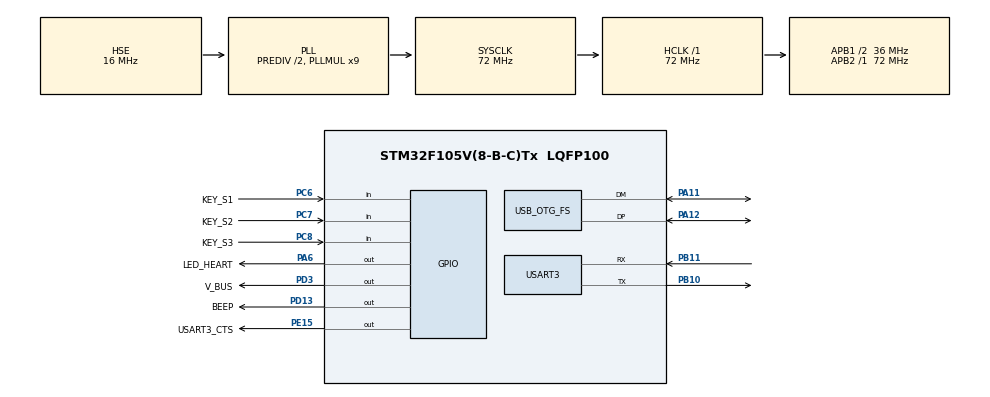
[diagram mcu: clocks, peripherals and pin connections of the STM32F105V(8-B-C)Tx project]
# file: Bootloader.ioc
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Dma.Request0=USART3_RX
Dma.Request1=USART3_TX
Dma.USART3_RX.0.Direction=DMA_PERIPH_TO_MEMORY
Dma.USART3_RX.0.Instance=DMA1_Channel3
Dma.USART3_RX.0.MemDataAlignment=DMA_MDATAALIGN_BYTE
Dma.USART3_RX.0.MemInc=DMA_MINC_ENABLE
Dma.USART3_RX.0.Mode=DMA_CIRCULAR
Dma.USART3_RX.0.PeriphDataAlignment=DMA_PDATAALIGN_BYTE
Dma.USART3_RX.0.PeriphInc=DMA_PINC_DISABLE
Dma.USART3_RX.0.Priority=DMA_PRIORITY_LOW
Dma.USART3_TX.1.Direction=DMA_MEMORY_TO_PERIPH
Dma.USART3_TX.1.Instance=DMA1_Channel2
Dma.USART3_TX.1.MemDataAlignment=DMA_MDATAALIGN_BYTE
Dma.USART3_TX.1.MemInc=DMA_MINC_ENABLE
Dma.USART3_TX.1.Mode=DMA_CIRCULAR
Dma.USART3_TX.1.PeriphDataAlignment=DMA_PDATAALIGN_BYTE
Dma.USART3_TX.1.PeriphInc=DMA_PINC_DISABLE
Dma.USART3_TX.1.Priority=DMA_PRIORITY_LOW
FATFS._FS_LOCK=1
FATFS._FS_NOFSINFO=0
FATFS._MAX_LFN=255
FATFS._MAX_SS=4096
FATFS._USE_LFN=1
Mcu.Family=STM32F1
Mcu.Name=STM32F105V(8-B-C)Tx
Mcu.Package=LQFP100
NVIC.DMA1_Channel2_IRQn=true\:0\:0\:false\:false\:true\:false\:true\:true
NVIC.DMA1_Channel3_IRQn=true\:0\:0\:false\:false\:true\:false\:true\:true
NVIC.OTG_FS_IRQn=true\:0\:0\:false\:false\:true\:false\:true\:true
NVIC.PriorityGroup=NVIC_PRIORITYGROUP_4
OSC_IN.Mode=HSE-External-Oscillator
OSC_IN.Signal=RCC_OSC_IN
OSC_OUT.Mode=HSE-External-Oscillator
OSC_OUT.Signal=RCC_OSC_OUT
PA11.Mode=Host_Only
PA11.Signal=USB_OTG_FS_DM
PA12.Mode=Host_Only
PA12.Signal=USB_OTG_FS_DP
PA13.Mode=Serial_Wire
PA13.Signal=SYS_JTMS-SWDIO
PA14.Mode=Serial_Wire
PA14.Signal=SYS_JTCK-SWCLK
PA6.GPIO_Label=LED_HEART
PA6.Signal=GPIO_Output
PB10.Mode=Asynchronous
PB10.Signal=USART3_TX
PB11.Mode=Asynchronous
PB11.Signal=USART3_RX
PC6.GPIO_Label=KEY_S1
PC6.Signal=GPIO_Input
PC7.GPIO_Label=KEY_S2
PC7.Signal=GPIO_Input
PC8.GPIO_Label=KEY_S3
PC8.Signal=GPIO_Input
PD13.GPIO_Label=BEEP
PD13.Signal=GPIO_Output
PD3.GPIO_Label=V_BUS
PD3.Signal=GPIO_Output
PE15.GPIO_Label=USART3_CTS
PE15.Signal=GPIO_Output
ProjectManager.HeapSize=0x200
ProjectManager.StackSize=0x400
ProjectManager.TargetToolchain=STM32CubeIDE
RCC.AHBFreq_Value=72000000
RCC.APB1CLKDivider=RCC_HCLK_DIV2
RCC.APB1Freq_Value=36000000
RCC.APB1TimFreq_Value=72000000
RCC.APB2Freq_Value=72000000
RCC.APB2TimFreq_Value=72000000
RCC.HCLKFreq_Value=72000000
RCC.HSEDivPLL=RCC_HSE_PREDIV_DIV2
RCC.HSE_VALUE=16000000
RCC.PLLMUL=RCC_PLL_MUL9
RCC.PLLSourceVirtual=RCC_PLLSOURCE_HSE
RCC.SYSCLKFreq_VALUE=72000000
RCC.SYSCLKSource=RCC_SYSCLKSOURCE_PLLCLK
RCC.USBFreq_Value=48000000
USART3.VirtualMode=VM_ASYNC
USB_HOST.BSP.number=1
USB_HOST.USBH_HandleTypeDef=hUsbHostFS
USB_HOST.VirtualModeFS=Msc
USB_HOST0.BSP.STBoard=false
USB_HOST0.BSP.api=Unknown
USB_HOST0.BSP.instance=PD3
USB_HOST0.BSP.ip=GPIO
USB_HOST0.BSP.mode=Output
USB_HOST0.BSP.name=Drive_VBUS_FS
USB_HOST0.BSP.solution=PD3
USB_OTG_FS.VirtualMode=Host_Only
VP_FATFS_VS_USB.Mode=USB
VP_USB_HOST_VS_USB_HOST_MSC_FS.Mode=MSC_FS
board=custom

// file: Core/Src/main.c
/* USER CODE BEGIN Header */
/**
  ******************************************************************************
  * @file           : main.c
  * @brief          : Main program body
  ******************************************************************************
  * @attention
  *
  * Copyright (c) 2023 STMicroelectronics.
  * All rights reserved.
  *
  * This software is licensed under terms that can be found in the LICENSE file
  * in the root directory of this software component.
  * If no LICENSE file comes with this software, it is provided AS-IS.
  *
  ******************************************************************************
  */
/* USER CODE END Header */
#include "main.h"
#include "fatfs.h"
#include "usb_host.h"

/* USER CODE BEGIN Includes */
#include "serial.h"
#include "Inc/DB_Protocol.h"
#include "_ver.h"

/* USER CODE END Includes */

UART_HandleTypeDef huart3;
DMA_HandleTypeDef hdma_usart3_rx;
DMA_HandleTypeDef hdma_usart3_tx;

void SystemClock_Config(void);
static void MX_GPIO_Init(void);
static void MX_DMA_Init(void);
static void MX_USART3_UART_Init(void);
void MX_USB_HOST_Process(void);

int main(void)
{

  /* MCU Configuration--------------------------------------------------------*/

  /* Reset of all peripherals, Initializes the Flash interface and the Systick. */
  HAL_Init();

  /* Configure the system clock */
  SystemClock_Config();

  /* Initialize all configured peripherals */
  MX_GPIO_Init();
  MX_DMA_Init();
  MX_FATFS_Init();
  MX_USB_HOST_Init();
  MX_USART3_UART_Init();
  /* USER CODE BEGIN 2 */
//jumpToApp(0x800C800);
	BootloaderInit();
 /* USER CODE END 2 */

  /* Infinite loop */
  while (1)
  {
    MX_USB_HOST_Process();

  }
}

void SystemClock_Config(void)
{
  RCC_OscInitTypeDef RCC_OscInitStruct = {0};
  RCC_ClkInitTypeDef RCC_ClkInitStruct = {0};
  RCC_PeriphCLKInitTypeDef PeriphClkInit = {0};

  /** Initializes the RCC Oscillators according to the specified parameters
  * in the RCC_OscInitTypeDef structure.
  */
  RCC_OscInitStruct.OscillatorType = RCC_OSCILLATORTYPE_HSE;
  RCC_OscInitStruct.HSEState = RCC_HSE_ON;
  RCC_OscInitStruct.HSEPredivValue = RCC_HSE_PREDIV_DIV2;
  RCC_OscInitStruct.HSIState = RCC_HSI_ON;
  RCC_OscInitStruct.Prediv1Source = RCC_PREDIV1_SOURCE_HSE;
  RCC_OscInitStruct.PLL.PLLState = RCC_PLL_ON;
  RCC_OscInitStruct.PLL.PLLSource = RCC_PLLSOURCE_HSE;
  RCC_OscInitStruct.PLL.PLLMUL = RCC_PLL_MUL9;
  RCC_OscInitStruct.PLL2.PLL2State = RCC_PLL_NONE;
  if (HAL_RCC_OscConfig(&RCC_OscInitStruct) != HAL_OK)
  {
    Error_Handler();
  }

  /** Initializes the CPU, AHB and APB buses clocks
  */
  RCC_ClkInitStruct.ClockType = RCC_CLOCKTYPE_HCLK|RCC_CLOCKTYPE_SYSCLK
                              |RCC_CLOCKTYPE_PCLK1|RCC_CLOCKTYPE_PCLK2;
  RCC_ClkInitStruct.SYSCLKSource = RCC_SYSCLKSOURCE_PLLCLK;
  RCC_ClkInitStruct.AHBCLKDivider = RCC_SYSCLK_DIV1;
  RCC_ClkInitStruct.APB1CLKDivider = RCC_HCLK_DIV2;
  RCC_ClkInitStruct.APB2CLKDivider = RCC_HCLK_DIV1;

  if (HAL_RCC_ClockConfig(&RCC_ClkInitStruct, FLASH_LATENCY_2) != HAL_OK)
  {
    Error_Handler();
  }
  PeriphClkInit.PeriphClockSelection = RCC_PERIPHCLK_USB;
  PeriphClkInit.UsbClockSelection = RCC_USBCLKSOURCE_PLL_DIV3;
  if (HAL_RCCEx_PeriphCLKConfig(&PeriphClkInit) != HAL_OK)
  {
    Error_Handler();
  }

  /** Configure the Systick interrupt time
  */
  __HAL_RCC_PLLI2S_ENABLE();
}

static void MX_USART3_UART_Init(void)
{

  huart3.Instance = USART3;
  huart3.Init.BaudRate = 115200;
  huart3.Init.WordLength = UART_WORDLENGTH_8B;
  huart3.Init.StopBits = UART_STOPBITS_1;
  huart3.Init.Parity = UART_PARITY_NONE;
  huart3.Init.Mode = UART_MODE_TX_RX;
  huart3.Init.HwFlowCtl = UART_HWCONTROL_NONE;
  huart3.Init.OverSampling = UART_OVERSAMPLING_16;
  if (HAL_UART_Init(&huart3) != HAL_OK)
  {
    Error_Handler();
  }

}

static void MX_DMA_Init(void)
{

  /* DMA controller clock enable */
  __HAL_RCC_DMA1_CLK_ENABLE();

  /* DMA interrupt init */
  /* DMA1_Channel2_IRQn interrupt configuration */
  HAL_NVIC_SetPriority(DMA1_Channel2_IRQn, 0, 0);
  HAL_NVIC_EnableIRQ(DMA1_Channel2_IRQn);
  /* DMA1_Channel3_IRQn interrupt configuration */
  HAL_NVIC_SetPriority(DMA1_Channel3_IRQn, 0, 0);
  HAL_NVIC_EnableIRQ(DMA1_Channel3_IRQn);

}

static void MX_GPIO_Init(void)
{
  GPIO_InitTypeDef GPIO_InitStruct = {0};

  /* GPIO Ports Clock Enable */
  __HAL_RCC_GPIOA_CLK_ENABLE();
  __HAL_RCC_GPIOE_CLK_ENABLE();
  __HAL_RCC_GPIOB_CLK_ENABLE();
  __HAL_RCC_GPIOD_CLK_ENABLE();
  __HAL_RCC_GPIOC_CLK_ENABLE();

  /*Configure GPIO pin Output Level */
  HAL_GPIO_WritePin(LED_HEART_GPIO_Port, LED_HEART_Pin, GPIO_PIN_RESET);

  /*Configure GPIO pin Output Level */
  HAL_GPIO_WritePin(USART3_CTS_GPIO_Port, USART3_CTS_Pin, GPIO_PIN_RESET);

  /*Configure GPIO pin Output Level */
  HAL_GPIO_WritePin(GPIOD, BEEP_Pin|V_BUS_Pin, GPIO_PIN_RESET);

  /*Configure GPIO pin : LED_HEART_Pin */
  GPIO_InitStruct.Pin = LED_HEART_Pin;
  GPIO_InitStruct.Mode = GPIO_MODE_OUTPUT_PP;
  GPIO_InitStruct.Pull = GPIO_NOPULL;
  GPIO_InitStruct.Speed = GPIO_SPEED_FREQ_LOW;
  HAL_GPIO_Init(LED_HEART_GPIO_Port, &GPIO_InitStruct);

  /*Configure GPIO pin : USART3_CTS_Pin */
  GPIO_InitStruct.Pin = USART3_CTS_Pin;
  GPIO_InitStruct.Mode = GPIO_MODE_OUTPUT_PP;
  GPIO_InitStruct.Pull = GPIO_NOPULL;
  GPIO_InitStruct.Speed = GPIO_SPEED_FREQ_LOW;
  HAL_GPIO_Init(USART3_CTS_GPIO_Port, &GPIO_InitStruct);

  /*Configure GPIO pins : BEEP_Pin V_BUS_Pin */
  GPIO_InitStruct.Pin = BEEP_Pin|V_BUS_Pin;
  GPIO_InitStruct.Mode = GPIO_MODE_OUTPUT_PP;
  GPIO_InitStruct.Pull = GPIO_NOPULL;
  GPIO_InitStruct.Speed = GPIO_SPEED_FREQ_LOW;
  HAL_GPIO_Init(GPIOD, &GPIO_InitStruct);

  /*Configure GPIO pins : KEY_S1_Pin KEY_S2_Pin KEY_S3_Pin */
  GPIO_InitStruct.Pin = KEY_S1_Pin|KEY_S2_Pin|KEY_S3_Pin;
  GPIO_InitStruct.Mode = GPIO_MODE_INPUT;
  GPIO_InitStruct.Pull = GPIO_NOPULL;
  HAL_GPIO_Init(GPIOC, &GPIO_InitStruct);

}

void Error_Handler(void)
{
  __disable_irq();
  while (1)
  {
  }
}
